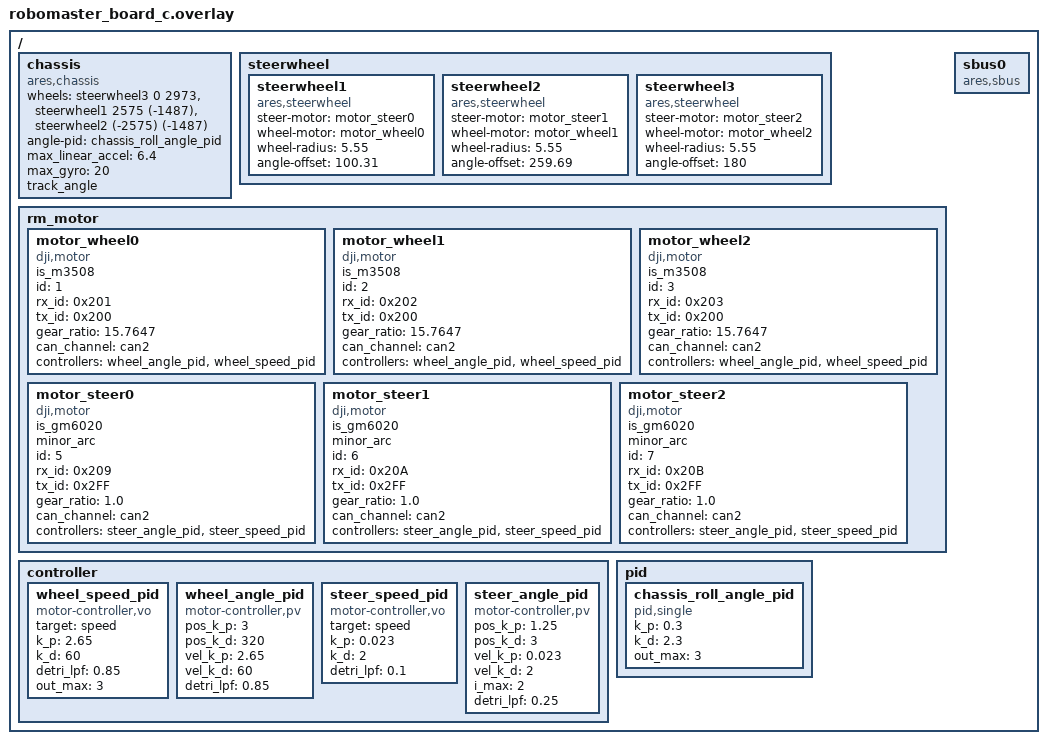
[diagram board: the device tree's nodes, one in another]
/ {
	chassis: chassis {
		compatible = "ares,chassis";
		status = "okay";
		wheels = <&steerwheel3  0 2973>,
				<&steerwheel1 2575 (-1487)>,
				<&steerwheel2 (-2575) (-1487)>;
		angle-pid = <&chassis_roll_angle_pid>;
		max_linear_accel = "6.4";
		max_gyro = "20";
		track_angle;
	};
	steerwheel {
		steerwheel1: steerwheel1 {
			#wheel-cells = <2>;
			compatible = "ares,steerwheel";
			status = "okay";
			steer-motor = <&motor_steer0>;
			wheel-motor = <&motor_wheel0>;
			wheel-radius = "5.55";
			angle-offset = "100.31";
		};

		steerwheel2: steerwheel2 {
			#wheel-cells = <2>;
			compatible = "ares,steerwheel";
			status = "okay";
			steer-motor = <&motor_steer1>;
			wheel-motor = <&motor_wheel1>;
			wheel-radius = "5.55";
			angle-offset = "259.69";
		};

		steerwheel3: steerwheel3 {
			#wheel-cells = <2>;
			compatible = "ares,steerwheel";
			status = "okay";
			steer-motor = <&motor_steer2>;
			wheel-motor = <&motor_wheel2>;
			wheel-radius = "5.55";
			angle-offset = "180";
		};
	};

	rm_motor {
		motor_wheel0: motor_wheel0{
			compatible = "dji,motor";
            is_m3508;
			id = <1>;
            rx_id = <0x201>;
            tx_id = <0x200>;
			gear_ratio = "15.7647";
			status = "okay";
			can_channel = <&can2>;
			controllers = <&wheel_angle_pid &wheel_speed_pid>;
		};

		motor_wheel1: motor_wheel1{
			compatible = "dji,motor";
            is_m3508;
			id = <2>;
            rx_id = <0x202>;
            tx_id = <0x200>;
			gear_ratio = "15.7647";
			status = "okay";
			can_channel = <&can2>;
			controllers = <&wheel_angle_pid &wheel_speed_pid>;
		};

		motor_wheel2: motor_wheel2{
			compatible = "dji,motor";
            is_m3508;
			id = <3>;
            rx_id = <0x203>;
            tx_id = <0x200>;
			gear_ratio = "15.7647";
			status = "okay";
			can_channel = <&can2>;
			controllers = <&wheel_angle_pid &wheel_speed_pid>;
		};

		motor_steer0: motor_steer0{
			compatible = "dji,motor";
			is_gm6020;
			minor_arc; // 必须配置此选项使之走劣弧
			id = <5>;
			rx_id = <0x209>;
			tx_id = <0x2FF>;
			gear_ratio = "1.0";
			status = "okay";
			can_channel = <&can2>;
			controllers = <&steer_angle_pid &steer_speed_pid>;
		};

		motor_steer1: motor_steer1{
			compatible = "dji,motor";
			is_gm6020;
			minor_arc; // 必须配置此选项使之走劣弧
			id = <6>;
			rx_id = <0x20A>;
			tx_id = <0x2FF>;
			gear_ratio = "1.0";
			status = "okay";
			can_channel = <&can2>;
			controllers = <&steer_angle_pid &steer_speed_pid>;
		};

		motor_steer2: motor_steer2{
			compatible = "dji,motor";
			is_gm6020;
			minor_arc; // 必须配置此选项使之走劣弧
			id = <7>;
			rx_id = <0x20B>;
			tx_id = <0x2FF>;
			gear_ratio = "1.0";
			status = "okay";
			can_channel = <&can2>;
			controllers = <&steer_angle_pid &steer_speed_pid>;
		};
	};

	controller {
		wheel_speed_pid: wheel_speed_pid {
			#controller-cells = <0>;
			compatible = "motor-controller,vo";
			target = "speed";
			k_p = "2.65";
			k_d = "60";
			detri_lpf = "0.85";
			out_max = "3";
		};

		wheel_angle_pid: wheel_angle_pid {
			#controller-cells = <0>;
			compatible = "motor-controller,pv";
			pos_k_p = "3";
			pos_k_d = "320";
			vel_k_p = "2.65";
			vel_k_d = "60";
			detri_lpf = "0.85";
		};

		steer_speed_pid: steer_speed_pid {
			#controller-cells = <0>;
			compatible = "motor-controller,vo";
			target = "speed";
			k_p = "0.023";
			k_d = "2";
			detri_lpf = "0.1";
		};

		steer_angle_pid: steer_angle_pid {
			#controller-cells = <0>;
			compatible = "motor-controller,pv";
			pos_k_p = "1.25";
			pos_k_d = "3";
			vel_k_p = "0.023";
			vel_k_d = "2";
			i_max = "2";
			detri_lpf = "0.25";
		};
	};

	pid {
		chassis_roll_angle_pid: chassis_roll_angle_pid {
			#controller-cells = <0>;
			compatible = "pid,single";
			k_p = "0.3";
			k_d = "2.3";
			out_max = "3";
		};
	};

	sbus0: sbus0 {
		compatible = "ares,sbus";
		status = "okay";
	};
};
